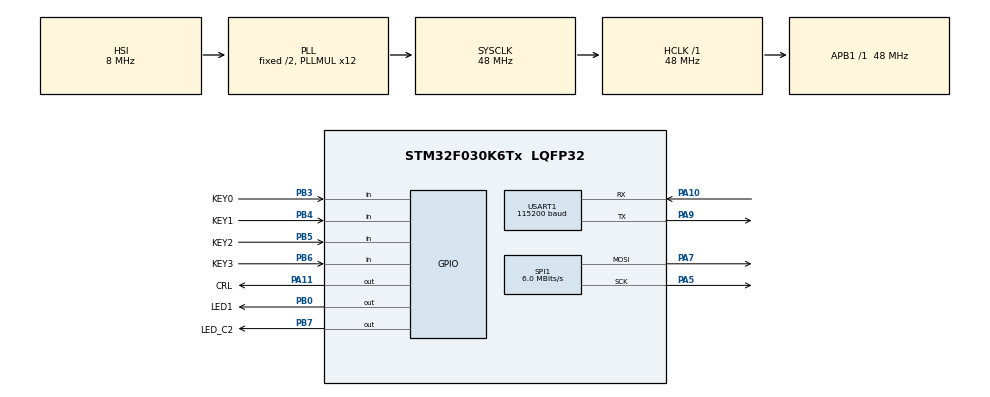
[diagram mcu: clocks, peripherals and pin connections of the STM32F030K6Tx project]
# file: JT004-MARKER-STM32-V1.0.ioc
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Dma.Request0=SPI1_TX
Dma.SPI1_TX.0.Direction=DMA_MEMORY_TO_PERIPH
Dma.SPI1_TX.0.Instance=DMA1_Channel3
Dma.SPI1_TX.0.MemDataAlignment=DMA_MDATAALIGN_BYTE
Dma.SPI1_TX.0.MemInc=DMA_MINC_ENABLE
Dma.SPI1_TX.0.Mode=DMA_NORMAL
Dma.SPI1_TX.0.PeriphDataAlignment=DMA_PDATAALIGN_BYTE
Dma.SPI1_TX.0.PeriphInc=DMA_PINC_DISABLE
Dma.SPI1_TX.0.Priority=DMA_PRIORITY_HIGH
IWDG.Prescaler=IWDG_PRESCALER_16
Mcu.Family=STM32F0
Mcu.Name=STM32F030K6Tx
Mcu.Package=LQFP32
NVIC.DMA1_Channel2_3_IRQn=true\:0\:0\:false\:false\:true\:false\:true\:true
NVIC.TIM17_IRQn=true\:3\:0\:true\:false\:true\:true\:true\:true
NVIC.USART1_IRQn=true\:0\:0\:false\:false\:true\:true\:true\:true
PA10.Mode=Asynchronous
PA10.Signal=USART1_RX
PA11.GPIO_Label=CRL
PA11.GPIO_PuPd=GPIO_PULLUP
PA11.Signal=GPIO_Output
PA13.Mode=Serial_Wire
PA13.Signal=SYS_SWDIO
PA14.Mode=Serial_Wire
PA14.Signal=SYS_SWCLK
PA5.Mode=TX_Only_Simplex_Unidirect_Master
PA5.Signal=SPI1_SCK
PA7.Mode=TX_Only_Simplex_Unidirect_Master
PA7.Signal=SPI1_MOSI
PA9.GPIO_PuPd=GPIO_PULLUP
PA9.Mode=Asynchronous
PA9.Signal=USART1_TX
PB0.GPIO_Label=LED1
PB0.PinState=GPIO_PIN_SET
PB0.Signal=GPIO_Output
PB3.GPIO_Label=KEY0
PB3.GPIO_PuPd=GPIO_PULLUP
PB3.Signal=GPIO_Input
PB4.GPIO_Label=KEY1
PB4.GPIO_PuPd=GPIO_PULLUP
PB4.Signal=GPIO_Input
PB5.GPIO_Label=KEY2
PB5.GPIO_PuPd=GPIO_PULLUP
PB5.Signal=GPIO_Input
PB6.GPIO_Label=KEY3
PB6.GPIO_PuPd=GPIO_PULLUP
PB6.Signal=GPIO_Input
PB7.GPIO_Label=LED_C2
PB7.GPIO_Speed=GPIO_SPEED_FREQ_HIGH
PB7.Signal=GPIO_Output
PF0-OSC_IN.Mode=HSE-External-Oscillator
PF0-OSC_IN.Signal=RCC_OSC_IN
PF1-OSC_OUT.Mode=HSE-External-Oscillator
PF1-OSC_OUT.Signal=RCC_OSC_OUT
ProjectManager.HeapSize=0x200
ProjectManager.StackSize=0x400
ProjectManager.TargetToolchain=CMake
RCC.AHBFreq_Value=48000000
RCC.APB1Freq_Value=48000000
RCC.APB1TimFreq_Value=48000000
RCC.HCLKFreq_Value=48000000
RCC.PLLMUL=RCC_PLL_MUL12
RCC.SYSCLKFreq_VALUE=48000000
RCC.SYSCLKSource=RCC_SYSCLKSOURCE_PLLCLK
SPI1.BaudRatePrescaler=SPI_BAUDRATEPRESCALER_8
SPI1.CalculateBaudRate=6.0 MBits/s
SPI1.DataSize=SPI_DATASIZE_8BIT
SPI1.Direction=SPI_DIRECTION_2LINES
SPI1.Mode=SPI_MODE_MASTER
SPI1.NSSPMode=SPI_NSS_PULSE_DISABLE
SPI1.VirtualType=VM_MASTER
TIM16.AutoReloadPreload=TIM_AUTORELOAD_PRELOAD_ENABLE
TIM16.Period=4-1
TIM17.AutoReloadPreload=TIM_AUTORELOAD_PRELOAD_ENABLE
TIM17.Period=1000-1
TIM17.Prescaler=48-1
USART1.BaudRate=115200
USART1.SwapParam=ADVFEATURE_SWAP_ENABLE
USART1.VirtualMode-Asynchronous=VM_ASYNC
VP_IWDG_VS_IWDG.Mode=IWDG_Activate
VP_TIM16_VS_ClockSourceINT.Mode=Enable_Timer
VP_TIM17_VS_ClockSourceINT.Mode=Enable_Timer
board=custom

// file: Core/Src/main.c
/* USER CODE BEGIN Header */
/**
  ******************************************************************************
  * @file           : main.c
  * @brief          : Main program body
  ******************************************************************************
  * @attention
  *
  * Copyright (c) 2026 STMicroelectronics.
  * All rights reserved.
  *
  * This software is licensed under terms that can be found in the LICENSE file
  * in the root directory of this software component.
  * If no LICENSE file comes with this software, it is provided AS-IS.
  *
  ******************************************************************************
  */
/* USER CODE END Header */
#include "main.h"
#include "dma.h"
#include "iwdg.h"
#include "spi.h"
#include "tim.h"
#include "usart.h"
#include "gpio.h"

/* USER CODE BEGIN Includes */
#include "app_task.h"
#include "bsp_usart.h"
/* USER CODE END Includes */

void SystemClock_Config(void);

int main(void)
{

  /* MCU Configuration--------------------------------------------------------*/

  /* Reset of all peripherals, Initializes the Flash interface and the Systick. */
  HAL_Init();

  /* Configure the system clock */
  SystemClock_Config();

  /* Initialize all configured peripherals */
  MX_GPIO_Init();
  MX_DMA_Init();
  MX_USART1_UART_Init();
  MX_TIM16_Init();
  MX_TIM17_Init();
  MX_IWDG_Init();
  MX_SPI1_Init();
  /* USER CODE BEGIN 2 */

    task();

  /* USER CODE END 2 */

  /* Infinite loop */
  while (1)
  {

  }
}

void SystemClock_Config(void)
{
  RCC_OscInitTypeDef RCC_OscInitStruct = {0};
  RCC_ClkInitTypeDef RCC_ClkInitStruct = {0};
  RCC_PeriphCLKInitTypeDef PeriphClkInit = {0};

  /** Initializes the RCC Oscillators according to the specified parameters
  * in the RCC_OscInitTypeDef structure.
  */
  RCC_OscInitStruct.OscillatorType = RCC_OSCILLATORTYPE_HSI|RCC_OSCILLATORTYPE_LSI;
  RCC_OscInitStruct.HSIState = RCC_HSI_ON;
  RCC_OscInitStruct.HSICalibrationValue = RCC_HSICALIBRATION_DEFAULT;
  RCC_OscInitStruct.LSIState = RCC_LSI_ON;
  RCC_OscInitStruct.PLL.PLLState = RCC_PLL_ON;
  RCC_OscInitStruct.PLL.PLLSource = RCC_PLLSOURCE_HSI;
  RCC_OscInitStruct.PLL.PLLMUL = RCC_PLL_MUL12;
  RCC_OscInitStruct.PLL.PREDIV = RCC_PREDIV_DIV1;
  if (HAL_RCC_OscConfig(&RCC_OscInitStruct) != HAL_OK)
  {
    Error_Handler();
  }

  /** Initializes the CPU, AHB and APB buses clocks
  */
  RCC_ClkInitStruct.ClockType = RCC_CLOCKTYPE_HCLK|RCC_CLOCKTYPE_SYSCLK
                              |RCC_CLOCKTYPE_PCLK1;
  RCC_ClkInitStruct.SYSCLKSource = RCC_SYSCLKSOURCE_PLLCLK;
  RCC_ClkInitStruct.AHBCLKDivider = RCC_SYSCLK_DIV1;
  RCC_ClkInitStruct.APB1CLKDivider = RCC_HCLK_DIV1;

  if (HAL_RCC_ClockConfig(&RCC_ClkInitStruct, FLASH_LATENCY_1) != HAL_OK)
  {
    Error_Handler();
  }
  PeriphClkInit.PeriphClockSelection = RCC_PERIPHCLK_USART1;
  PeriphClkInit.Usart1ClockSelection = RCC_USART1CLKSOURCE_PCLK1;
  if (HAL_RCCEx_PeriphCLKConfig(&PeriphClkInit) != HAL_OK)
  {
    Error_Handler();
  }
}

void Error_Handler(void)
{
  __disable_irq();
  while (1)
  {
  }
}
